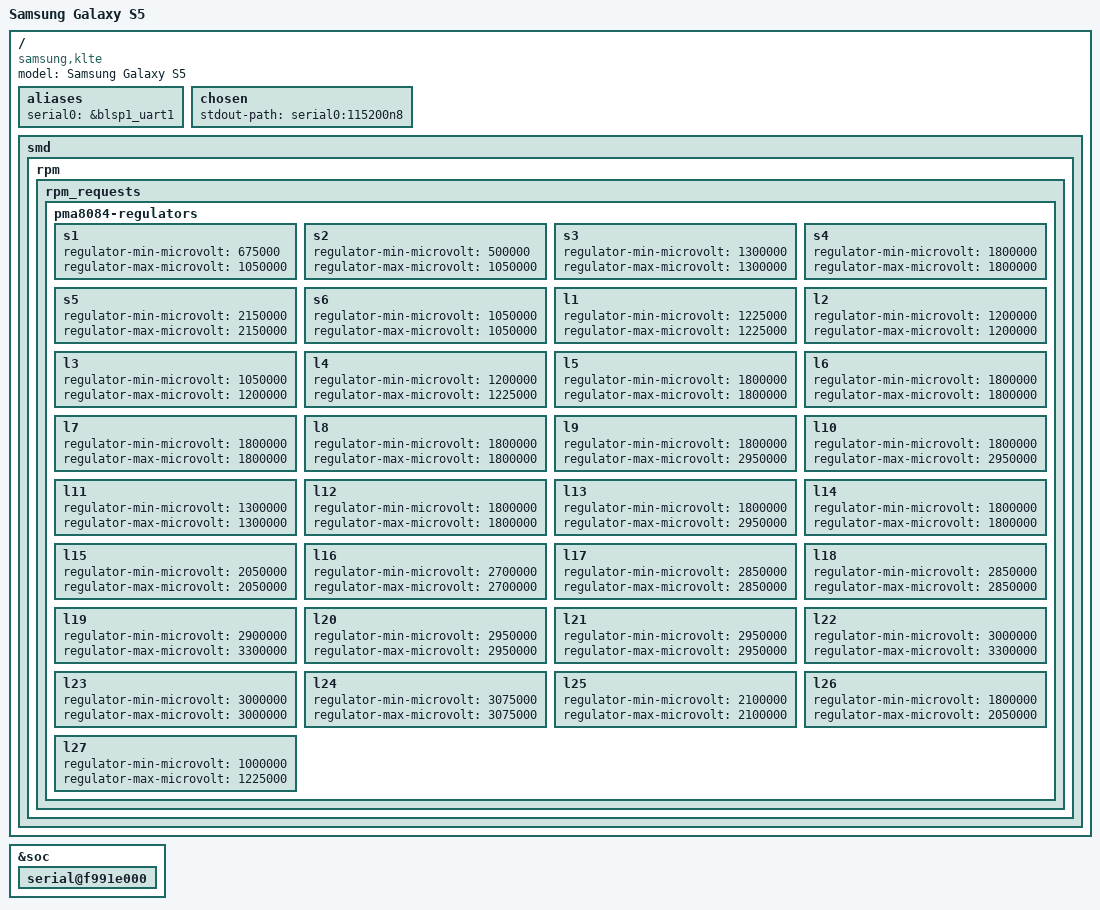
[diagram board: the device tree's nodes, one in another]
// SPDX-License-Identifier: GPL-2.0
#include "qcom-msm8974pro.dtsi"
#include "qcom-pm8841.dtsi"
#include "qcom-pm8941.dtsi"
#include "qcom-pma8084.dtsi"

/ {
	model = "Samsung Galaxy S5";
	compatible = "samsung,klte", "qcom,msm8974";

	aliases {
		serial0 = &blsp1_uart1;
	};

	chosen {
		stdout-path = "serial0:115200n8";
	};

	smd {
		rpm {
			rpm_requests {
				pma8084-regulators {
					status = "okay";

					s1 {
						regulator-min-microvolt = <675000>;
						regulator-max-microvolt = <1050000>;
					};

					s2 {
						regulator-min-microvolt = <500000>;
						regulator-max-microvolt = <1050000>;
					};

					s3 {
						regulator-min-microvolt = <1300000>;
						regulator-max-microvolt = <1300000>;
					};

					s4 {
						regulator-min-microvolt = <1800000>;
						regulator-max-microvolt = <1800000>;
					};

					s5 {
						regulator-min-microvolt = <2150000>;
						regulator-max-microvolt = <2150000>;
					};

					s6 {
						regulator-min-microvolt = <1050000>;
						regulator-max-microvolt = <1050000>;
					};

					l1 {
						regulator-min-microvolt = <1225000>;
						regulator-max-microvolt = <1225000>;
					};

					l2 {
						regulator-min-microvolt = <1200000>;
						regulator-max-microvolt = <1200000>;
					};

					l3 {
						regulator-min-microvolt = <1050000>;
						regulator-max-microvolt = <1200000>;
					};

					l4 {
						regulator-min-microvolt = <1200000>;
						regulator-max-microvolt = <1225000>;
					};

					l5 {
						regulator-min-microvolt = <1800000>;
						regulator-max-microvolt = <1800000>;
					};

					l6 {
						regulator-min-microvolt = <1800000>;
						regulator-max-microvolt = <1800000>;
					};

					l7 {
						regulator-min-microvolt = <1800000>;
						regulator-max-microvolt = <1800000>;
					};

					l8 {
						regulator-min-microvolt = <1800000>;
						regulator-max-microvolt = <1800000>;
					};

					l9 {
						regulator-min-microvolt = <1800000>;
						regulator-max-microvolt = <2950000>;
					};

					l10 {
						regulator-min-microvolt = <1800000>;
						regulator-max-microvolt = <2950000>;
					};

					l11 {
						regulator-min-microvolt = <1300000>;
						regulator-max-microvolt = <1300000>;
					};

					l12 {
						regulator-min-microvolt = <1800000>;
						regulator-max-microvolt = <1800000>;
					};

					l13 {
						regulator-min-microvolt = <1800000>;
						regulator-max-microvolt = <2950000>;
					};

					l14 {
						regulator-min-microvolt = <1800000>;
						regulator-max-microvolt = <1800000>;
					};

					l15 {
						regulator-min-microvolt = <2050000>;
						regulator-max-microvolt = <2050000>;
					};

					l16 {
						regulator-min-microvolt = <2700000>;
						regulator-max-microvolt = <2700000>;
					};

					l17 {
						regulator-min-microvolt = <2850000>;
						regulator-max-microvolt = <2850000>;
					};

					l18 {
						regulator-min-microvolt = <2850000>;
						regulator-max-microvolt = <2850000>;
					};

					l19 {
						regulator-min-microvolt = <2900000>;
						regulator-max-microvolt = <3300000>;
					};

					l20 {
						regulator-min-microvolt = <2950000>;
						regulator-max-microvolt = <2950000>;
					};

					l21 {
						regulator-min-microvolt = <2950000>;
						regulator-max-microvolt = <2950000>;
					};

					l22 {
						regulator-min-microvolt = <3000000>;
						regulator-max-microvolt = <3300000>;
					};

					l23 {
						regulator-min-microvolt = <3000000>;
						regulator-max-microvolt = <3000000>;
					};

					l24 {
						regulator-min-microvolt = <3075000>;
						regulator-max-microvolt = <3075000>;
					};

					l25 {
						regulator-min-microvolt = <2100000>;
						regulator-max-microvolt = <2100000>;
					};

					l26 {
						regulator-min-microvolt = <1800000>;
						regulator-max-microvolt = <2050000>;
					};

					l27 {
						regulator-min-microvolt = <1000000>;
						regulator-max-microvolt = <1225000>;
					};
				};
			};
		};
	};
};

&soc {
	serial@f991e000 {
		status = "ok";
	};

};
